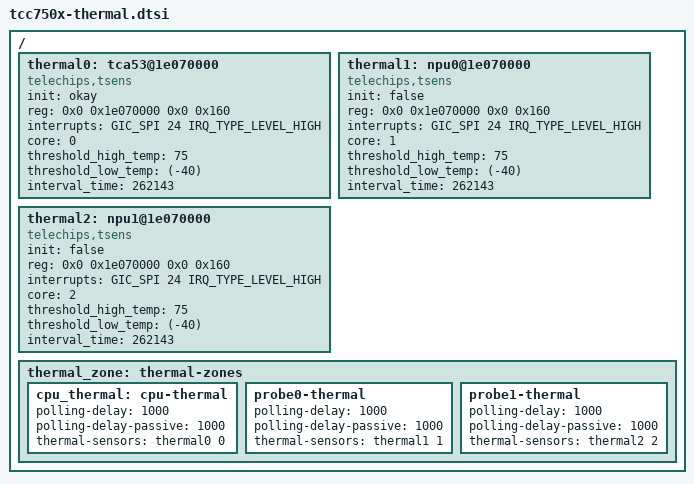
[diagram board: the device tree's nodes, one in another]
// SPDX-License-Identifier: (GPL-2.0-or-later OR MIT)
/*
 * Copyright (C) 2023 Telechips Inc.
 */

#include <dt-bindings/interrupt-controller/arm-gic.h>
#include <dt-bindings/thermal/thermal.h>

/ {
	thermal0: tca53@1e070000 {
		compatible = "telechips,tsens";

		init = "okay";
		reg = <0x0 0x1e070000 0x0 0x160>; //0:Enable register
		status = "okay";

		interrupts = <GIC_SPI 24 IRQ_TYPE_LEVEL_HIGH>;
		core = <0>;

		threshold_high_temp = <75>;
		threshold_low_temp = <(-40)>;
		interval_time = <262143>;
		#thermal-sensor-cells = <1>;
	};

	thermal1: npu0@1e070000 {
		compatible = "telechips,tsens";

		init = "false";
		reg = <0x0 0x1e070000 0x0 0x160>; //0:Enable register
		status = "okay";

		interrupts = <GIC_SPI 24 IRQ_TYPE_LEVEL_HIGH>;
		core = <1>;

		threshold_high_temp = <75>;
		threshold_low_temp = <(-40)>;
		interval_time = <262143>;
		#thermal-sensor-cells = <1>;
	};

	thermal2: npu1@1e070000 {
		compatible = "telechips,tsens";

		init = "false";
		reg = <0x0 0x1e070000 0x0 0x160>; //0:Enable register
		status = "okay";

		interrupts = <GIC_SPI 24 IRQ_TYPE_LEVEL_HIGH>;
		core = <2>;

		threshold_high_temp = <75>;
		threshold_low_temp = <(-40)>;
		interval_time = <262143>;
		#thermal-sensor-cells = <1>;
	};

	thermal_zone: thermal-zones {
		cpu_thermal: cpu-thermal {
			polling-delay = <1000>;
			polling-delay-passive = <1000>;
			thermal-sensors = <&thermal0 0>;
		};

		probe0-thermal {
			polling-delay = <1000>;
			polling-delay-passive = <1000>;
			thermal-sensors = <&thermal1 1>;
		};

		probe1-thermal {
			polling-delay = <1000>;
			polling-delay-passive = <1000>;
			thermal-sensors = <&thermal2 2>;
		};
	};
};
